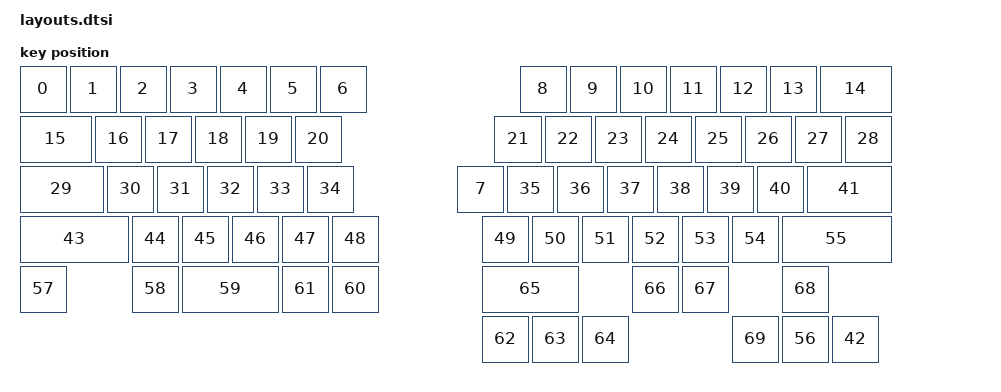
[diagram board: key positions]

#include <physical_layouts.dtsi>
/ {
    physical_layout0: physical_layout0 {
        compatible = "zmk,physical-layout";
        display-name = "Layout";
        keys
            = <&key_physical_attrs 100 100 (-50) 0 0 0 0>
			,<&key_physical_attrs 100 100 50 0 0 0 0>
			,<&key_physical_attrs 100 100 150 0 0 0 0>
			,<&key_physical_attrs 100 100 250 0 0 0 0>
			,<&key_physical_attrs 100 100 350 0 0 0 0>
			,<&key_physical_attrs 100 100 450 0 0 0 0>
			,<&key_physical_attrs 100 100 550 0 0 0 0>
			,<&key_physical_attrs 100 100 825 200 0 0 0>
			,<&key_physical_attrs 100 100 950 0 0 0 0>
			,<&key_physical_attrs 100 100 1050 0 0 0 0>
			,<&key_physical_attrs 100 100 1150 0 0 0 0>
			,<&key_physical_attrs 100 100 1250 0 0 0 0>
			,<&key_physical_attrs 100 100 1350 0 0 0 0>
			,<&key_physical_attrs 100 100 1450 0 0 0 0>
			,<&key_physical_attrs 150 100 1550 0 0 0 0>
			,<&key_physical_attrs 150 100 (-50) 100 0 0 0>
			,<&key_physical_attrs 100 100 100 100 0 0 0>
			,<&key_physical_attrs 100 100 200 100 0 0 0>
			,<&key_physical_attrs 100 100 300 100 0 0 0>
			,<&key_physical_attrs 100 100 400 100 0 0 0>
			,<&key_physical_attrs 100 100 500 100 0 0 0>
			,<&key_physical_attrs 100 100 900 100 0 0 0>
			,<&key_physical_attrs 100 100 1000 100 0 0 0>
			,<&key_physical_attrs 100 100 1100 100 0 0 0>
			,<&key_physical_attrs 100 100 1200 100 0 0 0>
			,<&key_physical_attrs 100 100 1300 100 0 0 0>
			,<&key_physical_attrs 100 100 1400 100 0 0 0>
			,<&key_physical_attrs 100 100 1500 100 0 0 0>
			,<&key_physical_attrs 100 100 1600 100 0 0 0>
			,<&key_physical_attrs 175 100 (-50) 200 0 0 0>
			,<&key_physical_attrs 100 100 125 200 0 0 0>
			,<&key_physical_attrs 100 100 225 200 0 0 0>
			,<&key_physical_attrs 100 100 325 200 0 0 0>
			,<&key_physical_attrs 100 100 425 200 0 0 0>
			,<&key_physical_attrs 100 100 525 200 0 0 0>
			,<&key_physical_attrs 100 100 925 200 0 0 0>
			,<&key_physical_attrs 100 100 1025 200 0 0 0>
			,<&key_physical_attrs 100 100 1125 200 0 0 0>
			,<&key_physical_attrs 100 100 1225 200 0 0 0>
			,<&key_physical_attrs 100 100 1325 200 0 0 0>
			,<&key_physical_attrs 100 100 1425 200 0 0 0>
			,<&key_physical_attrs 175 100 1525 200 0 0 0>
			,<&key_physical_attrs 100 100 1575 500 0 0 0>
			,<&key_physical_attrs 225 100 (-50) 300 0 0 0>
			,<&key_physical_attrs 100 100 175 300 0 0 0>
			,<&key_physical_attrs 100 100 275 300 0 0 0>
			,<&key_physical_attrs 100 100 375 300 0 0 0>
			,<&key_physical_attrs 100 100 475 300 0 0 0>
			,<&key_physical_attrs 100 100 575 300 0 0 0>
			,<&key_physical_attrs 100 100 875 300 0 0 0>
			,<&key_physical_attrs 100 100 975 300 0 0 0>
			,<&key_physical_attrs 100 100 1075 300 0 0 0>
			,<&key_physical_attrs 100 100 1175 300 0 0 0>
			,<&key_physical_attrs 100 100 1275 300 0 0 0>
			,<&key_physical_attrs 100 100 1375 300 0 0 0>
			,<&key_physical_attrs 225 100 1475 300 0 0 0>
			,<&key_physical_attrs 100 100 1475 500 0 0 0>
			,<&key_physical_attrs 100 100 (-50) 400 0 0 0>
			,<&key_physical_attrs 100 100 175 400 0 0 0>
			,<&key_physical_attrs 200 100 275 400 0 0 0>
			,<&key_physical_attrs 100 100 575 400 0 0 0>
			,<&key_physical_attrs 100 100 475 400 0 0 0>
			,<&key_physical_attrs 100 100 875 500 0 0 0>
			,<&key_physical_attrs 100 100 975 500 0 0 0>
			,<&key_physical_attrs 100 100 1075 500 0 0 0>
			,<&key_physical_attrs 200 100 875 400 0 0 0>
			,<&key_physical_attrs 100 100 1175 400 0 0 0>
			,<&key_physical_attrs 100 100 1275 400 0 0 0>
			,<&key_physical_attrs 100 100 1475 400 0 0 0>
			,<&key_physical_attrs 100 100 1375 500 0 0 0>
            ;
    };
};
    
